# ECC_AGGR2_ECC_AGGR register map
Vendor: Texas Instruments
Peripheral module from a debugger description file (folder am65x).
Registers are 32-bit, access not given, reset 0x0 unless marked. A register's access mark holds for its fields unless they carry their own. Offsets are as the file gives them; lines under a group give offsets from that group; [hi:lo] are bit positions; {n}, {i} and the like mark numbered series; 'fields as' and 'values as' point back to an identical list; <NAME> marks a mode.

## ECC_AGGR2_ECC_AGGR
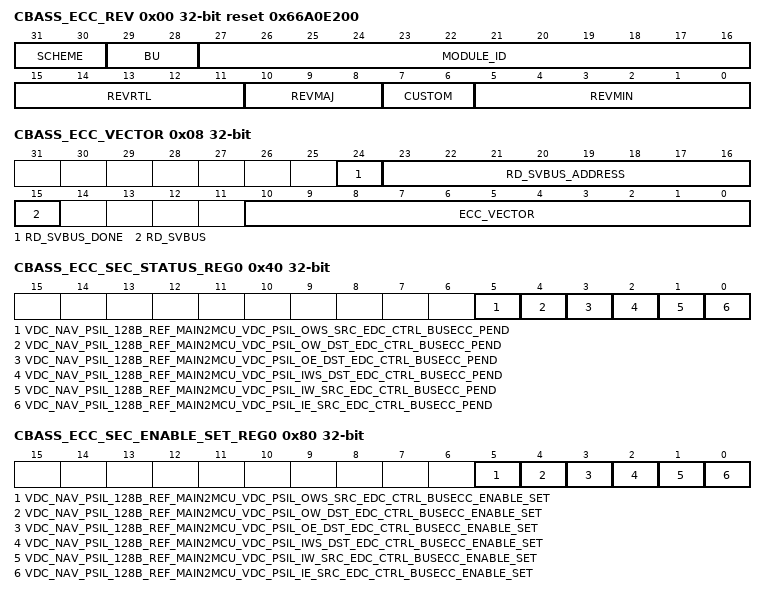
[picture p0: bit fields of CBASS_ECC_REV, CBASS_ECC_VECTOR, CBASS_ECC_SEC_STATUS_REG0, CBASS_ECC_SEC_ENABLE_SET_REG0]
0x00 CBASS_ECC_REV ro reset 0x66A0E200 — Return to the . Revision parameters
  [31:30] SCHEME
  [29:28] BU
  [27:16] MODULE_ID
  [15:11] REVRTL — RTL version
  [10:8] REVMAJ — Major version
  [7:6] CUSTOM — Custom version
  [5:0] REVMIN — Minor version
0x08 CBASS_ECC_VECTOR — Return to the . ECC Vector Register
  [24] RD_SVBUS_DONE — Status to indicate if read on serial VBUS is complete, write of any value will clear this bit. (access RW1C)
  [23:16] RD_SVBUS_ADDRESS rw — Read address
  [15] RD_SVBUS — Write 1 to trigger a read on the serial VBUS (access RW1S)
  [10:0] ECC_VECTOR rw — Value written to select the corresponding ECC RAM for control or status
0x0C CBASS_ECC_STAT ro reset 0x6 — Return to the . Misc Status
  [10:0] NUM_RAMS — Indicates the number of RAMS serviced by the ECC aggregator
0x3C CBASS_ECC_SEC_EOI_REG — Return to the . EOI Register
  [0] EOI_WR — EOI Register (access RW1S)
0x40 CBASS_ECC_SEC_STATUS_REG0 — Return to the . Interrupt Status Register 0
  [5] VDC_NAV_PSIL_128B_REF_MAIN2MCU_VDC_PSIL_OWS_SRC_EDC_CTRL_BUSECC_PEND — Interrupt Pending Status for vdc_nav_psil_128b_ref_main2mcu_vdc_psil_ows_src_edc_ctrl_busecc__pend (access RW1S)
  [4] VDC_NAV_PSIL_128B_REF_MAIN2MCU_VDC_PSIL_OW_DST_EDC_CTRL_BUSECC_PEND — Interrupt Pending Status for vdc_nav_psil_128b_ref_main2mcu_vdc_psil_ow_dst_edc_ctrl_busecc__pend (access RW1S)
  [3] VDC_NAV_PSIL_128B_REF_MAIN2MCU_VDC_PSIL_OE_DST_EDC_CTRL_BUSECC_PEND — Interrupt Pending Status for vdc_nav_psil_128b_ref_main2mcu_vdc_psil_oe_dst_edc_ctrl_busecc__pend (access RW1S)
  [2] VDC_NAV_PSIL_128B_REF_MAIN2MCU_VDC_PSIL_IWS_DST_EDC_CTRL_BUSECC_PEND — Interrupt Pending Status for vdc_nav_psil_128b_ref_main2mcu_vdc_psil_iws_dst_edc_ctrl_busecc__pend (access RW1S)
  [1] VDC_NAV_PSIL_128B_REF_MAIN2MCU_VDC_PSIL_IW_SRC_EDC_CTRL_BUSECC_PEND — Interrupt Pending Status for vdc_nav_psil_128b_ref_main2mcu_vdc_psil_iw_src_edc_ctrl_busecc__pend (access RW1S)
  [0] VDC_NAV_PSIL_128B_REF_MAIN2MCU_VDC_PSIL_IE_SRC_EDC_CTRL_BUSECC_PEND — Interrupt Pending Status for vdc_nav_psil_128b_ref_main2mcu_vdc_psil_ie_src_edc_ctrl_busecc__pend (access RW1S)
0x80 CBASS_ECC_SEC_ENABLE_SET_REG0 — Return to the . Interrupt Enable Set Register 0
  [5] VDC_NAV_PSIL_128B_REF_MAIN2MCU_VDC_PSIL_OWS_SRC_EDC_CTRL_BUSECC_ENABLE_SET — Interrupt Enable Set Register for vdc_nav_psil_128b_ref_main2mcu_vdc_psil_ows_src_edc_ctrl_busecc__pend (access RW1S)
  [4] VDC_NAV_PSIL_128B_REF_MAIN2MCU_VDC_PSIL_OW_DST_EDC_CTRL_BUSECC_ENABLE_SET — Interrupt Enable Set Register for vdc_nav_psil_128b_ref_main2mcu_vdc_psil_ow_dst_edc_ctrl_busecc__pend (access RW1S)
  [3] VDC_NAV_PSIL_128B_REF_MAIN2MCU_VDC_PSIL_OE_DST_EDC_CTRL_BUSECC_ENABLE_SET — Interrupt Enable Set Register for vdc_nav_psil_128b_ref_main2mcu_vdc_psil_oe_dst_edc_ctrl_busecc__pend (access RW1S)
  [2] VDC_NAV_PSIL_128B_REF_MAIN2MCU_VDC_PSIL_IWS_DST_EDC_CTRL_BUSECC_ENABLE_SET — Interrupt Enable Set Register for vdc_nav_psil_128b_ref_main2mcu_vdc_psil_iws_dst_edc_ctrl_busecc__pend (access RW1S)
  [1] VDC_NAV_PSIL_128B_REF_MAIN2MCU_VDC_PSIL_IW_SRC_EDC_CTRL_BUSECC_ENABLE_SET — Interrupt Enable Set Register for vdc_nav_psil_128b_ref_main2mcu_vdc_psil_iw_src_edc_ctrl_busecc__pend (access RW1S)
  [0] VDC_NAV_PSIL_128B_REF_MAIN2MCU_VDC_PSIL_IE_SRC_EDC_CTRL_BUSECC_ENABLE_SET — Interrupt Enable Set Register for vdc_nav_psil_128b_ref_main2mcu_vdc_psil_ie_src_edc_ctrl_busecc__pend (access RW1S)
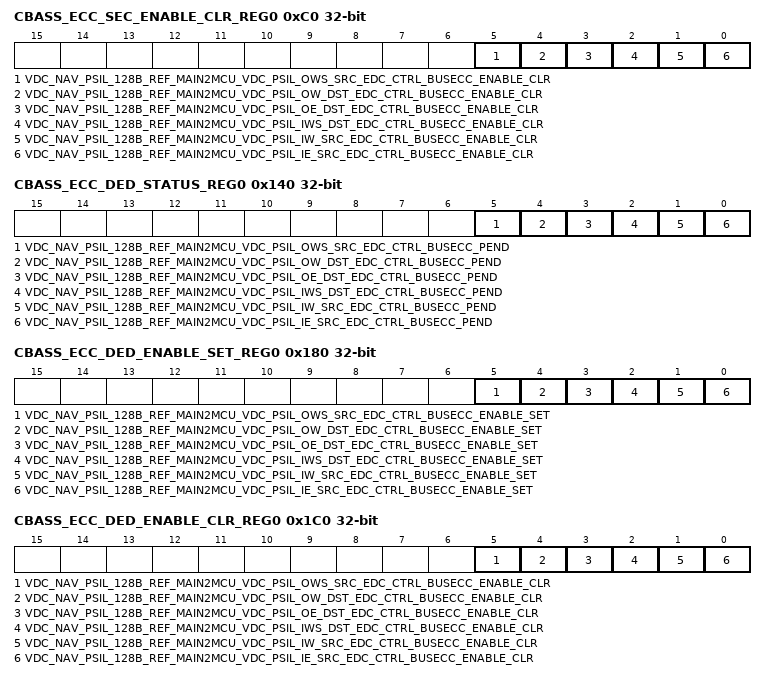
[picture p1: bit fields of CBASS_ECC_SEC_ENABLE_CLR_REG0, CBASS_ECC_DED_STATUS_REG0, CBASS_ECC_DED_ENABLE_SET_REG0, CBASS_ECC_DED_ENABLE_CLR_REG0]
0xC0 CBASS_ECC_SEC_ENABLE_CLR_REG0 — Return to the . Interrupt Enable Clear Register 0
  [5] VDC_NAV_PSIL_128B_REF_MAIN2MCU_VDC_PSIL_OWS_SRC_EDC_CTRL_BUSECC_ENABLE_CLR — Interrupt Enable Clear Register for vdc_nav_psil_128b_ref_main2mcu_vdc_psil_ows_src_edc_ctrl_busecc__pend (access RW1C)
  [4] VDC_NAV_PSIL_128B_REF_MAIN2MCU_VDC_PSIL_OW_DST_EDC_CTRL_BUSECC_ENABLE_CLR — Interrupt Enable Clear Register for vdc_nav_psil_128b_ref_main2mcu_vdc_psil_ow_dst_edc_ctrl_busecc__pend (access RW1C)
  [3] VDC_NAV_PSIL_128B_REF_MAIN2MCU_VDC_PSIL_OE_DST_EDC_CTRL_BUSECC_ENABLE_CLR — Interrupt Enable Clear Register for vdc_nav_psil_128b_ref_main2mcu_vdc_psil_oe_dst_edc_ctrl_busecc__pend (access RW1C)
  [2] VDC_NAV_PSIL_128B_REF_MAIN2MCU_VDC_PSIL_IWS_DST_EDC_CTRL_BUSECC_ENABLE_CLR — Interrupt Enable Clear Register for vdc_nav_psil_128b_ref_main2mcu_vdc_psil_iws_dst_edc_ctrl_busecc__pend (access RW1C)
  [1] VDC_NAV_PSIL_128B_REF_MAIN2MCU_VDC_PSIL_IW_SRC_EDC_CTRL_BUSECC_ENABLE_CLR — Interrupt Enable Clear Register for vdc_nav_psil_128b_ref_main2mcu_vdc_psil_iw_src_edc_ctrl_busecc__pend (access RW1C)
  [0] VDC_NAV_PSIL_128B_REF_MAIN2MCU_VDC_PSIL_IE_SRC_EDC_CTRL_BUSECC_ENABLE_CLR — Interrupt Enable Clear Register for vdc_nav_psil_128b_ref_main2mcu_vdc_psil_ie_src_edc_ctrl_busecc__pend (access RW1C)
0x13C CBASS_ECC_DED_EOI_REG — Return to the . EOI Register
  [0] EOI_WR — EOI Register (access RW1S)
0x140 CBASS_ECC_DED_STATUS_REG0 — Return to the . Interrupt Status Register 0
  fields as CBASS_ECC_SEC_STATUS_REG0
0x180 CBASS_ECC_DED_ENABLE_SET_REG0 — Return to the . Interrupt Enable Set Register 0
  fields as CBASS_ECC_SEC_ENABLE_SET_REG0
0x1C0 CBASS_ECC_DED_ENABLE_CLR_REG0 — Return to the . Interrupt Enable Clear Register 0
  fields as CBASS_ECC_SEC_ENABLE_CLR_REG0
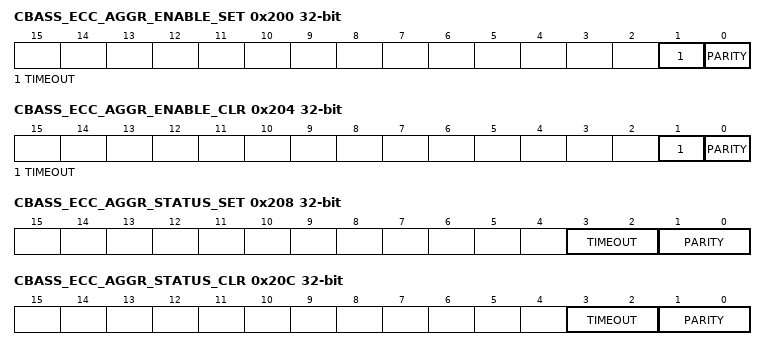
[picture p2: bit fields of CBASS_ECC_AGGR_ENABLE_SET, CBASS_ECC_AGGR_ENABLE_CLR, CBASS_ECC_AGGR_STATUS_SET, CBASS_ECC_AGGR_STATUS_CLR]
0x200 CBASS_ECC_AGGR_ENABLE_SET — Return to the . AGGR interrupt enable set Register
  [1] TIMEOUT — interrupt enable set for svbus timeout errors (access RW1S)
  [0] PARITY — interrupt enable set for parity errors (access RW1S)
0x204 CBASS_ECC_AGGR_ENABLE_CLR — Return to the . AGGR interrupt enable clear Register
  [1] TIMEOUT — interrupt enable clear for svbus timeout errors (access RW1C)
  [0] PARITY — interrupt enable clear for parity errors (access RW1C)
0x208 CBASS_ECC_AGGR_STATUS_SET rw — Return to the . AGGR interrupt status set Register
  [3:2] TIMEOUT — interrupt status set for svbus timeout errors
  [1:0] PARITY — interrupt status set for parity errors
0x20C CBASS_ECC_AGGR_STATUS_CLR rw — Return to the . AGGR interrupt status clear Register
  [3:2] TIMEOUT — interrupt status clear for svbus timeout errors
  [1:0] PARITY — interrupt status clear for parity errors
